# cc13x2_cc26x2 register map
File version: 2.1
CPU: CM4 r0p1, little endian, MPU, FPU, 3 interrupt priority bits
Registers are 32-bit, read-write, reset 0x0 unless marked. A register's access mark holds for its fields unless they carry their own. Offsets are from the block's base; [hi:lo] are bit positions.

## PKA — Integrated module which combines the Public Key Acceleration module, optional True Random Gnerator, optional interrupt controller and a standard bus interface
Base 0x40025000
0x00 APTR — PKA Vector A Address uring execution of basic PKCP operations, this register is double buffered and can be written with a new value for the next operation; when not written, the value remains intact. During the execution of sequencer-controlled complex operations, this register may not be written and its value is undefined at the conclusion of the operation. The driver software cannot rely on the written value to remain intact.
  [10:0] APTR
0x04 BPTR — PKA Vector B Address uring execution of basic PKCP operations, this register is double buffered and can be written with a new value for the next operation; when not written, the value remains intact. During the execution of sequencer-controlled complex operations, this register may not be written and its value is undefined at the conclusion of the operation. The driver software cannot rely on the written value to remain intact.
  [10:0] BPTR
0x08 CPTR — PKA Vector C Address uring execution of basic PKCP operations, this register is double buffered and can be written with a new value for the next operation; when not written, the value remains intact. During the execution of sequencer-controlled complex operations, this register may not be written and its value is undefined at the conclusion of the operation. The driver software cannot rely on the written value to remain intact.
  [10:0] CPTR
0x0C DPTR — PKA Vector D Address uring execution of basic PKCP operations, this register is double buffered and can be written with a new value for the next operation; when not written, the value remains intact. During the execution of sequencer-controlled complex operations, this register may not be written and its value is undefined at the conclusion of the operation. The driver software cannot rely on the written value to remain intact.
  [10:0] DPTR
0x10 ALENGTH — PKA Vector A Length uring execution of basic PKCP operations, this register is double buffered and can be written with a new value for the next operation; when not written, the value remains intact. During the execution of sequencer-controlled complex operations, this register may not be written and its value is undefined at the conclusion of the operation. The driver software cannot rely on the written value to remain intact.
  [8:0] ALENGTH
0x14 BLENGTH — PKA Vector B Length uring execution of basic PKCP operations, this register is double buffered and can be written with a new value for the next operation; when not written, the value remains intact. During the execution of sequencer-controlled complex operations, this register may not be written and its value is undefined at the conclusion of the operation. The driver software cannot rely on the written value to remain intact.
  [8:0] BLENGTH
0x18 SHIFT — PKA Bit Shift Value or basic PKCP operations, modifying the contents of this register is made impossible while the operation is being performed. For the ExpMod-variable and ExpMod-CRT operations, this register is used to indicate the number of odd powers to use (directly as a value in the range 1-16). For the ModInv and ECC operations, this register is used to hold a completion code.
  [4:0] NUM_BITS_TO_SHIFT
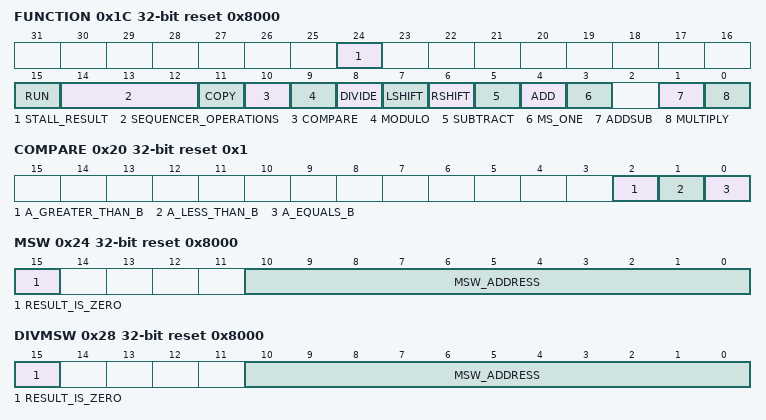
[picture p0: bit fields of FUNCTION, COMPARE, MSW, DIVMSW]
0x1C FUNCTION reset 0x8000 — PKA Function his register contains the control bits to start basic PKCP as well as complex sequencer operations. The run bit can be used to poll for the completion of the operation. Modifying bits [11:0] is made impossible during the execution of a basic PKCP operation. uring the execution of sequencer-controlled complex operations, this register is modified, the run and stall result bits are set to zero at the conclusion, but other bits are undefined. OTE: Continuously reading this register to poll the run bit is not allowed when executing complex sequencer operations (the sequencer cannot access the PKCP when this is done). Leave at least one sysclk cycle between poll operations.
  [24] STALL_RESULT, [15] RUN, [14:12] SEQUENCER_OPERATIONS, [11] COPY, [10] COMPARE, [9] MODULO, [8] DIVIDE, [7] LSHIFT, [6] RSHIFT, [5] SUBTRACT, [4] ADD, [3] MS_ONE, [1] ADDSUB, [0] MULTIPLY
0x20 COMPARE ro reset 0x1 — PKA compare result his register provides the result of a basic PKCP compare operation. It is updated when the FUNCTION.RUN bit is reset at the end of that operation. tatus after a complex sequencer operation is unknown
  [2] A_GREATER_THAN_B, [1] A_LESS_THAN_B, [0] A_EQUALS_B
0x24 MSW ro reset 0x8000 — PKA most-significant-word of result vector his register indicates the (word) address in the PKA RAM where the most significant nonzero 32-bit word of the result is stored. Should be ignored for modulo operations. For basic PKCP operations, this register is updated FUNCTION.RUN bit is reset at the end of the operation. For the complex-sequencer controlled operations, updating of the final value matching the actual result is done near the end of the operation; note that the result is only meaningful if no errors were detected and that for ECC operations, this register will provide information for the x-coordinate of the result point only.
  [15] RESULT_IS_ZERO, [10:0] MSW_ADDRESS
0x28 DIVMSW ro reset 0x8000 — PKA most-significant-word of divide remainder his register indicates the (32-bit word) address in the PKA RAM where the most significant nonzero 32-bit word of the remainder result for the basic divide and modulo operations is stored. Bits [4:0] are loaded with the bit number of the most-significant nonzero bit in the most-significant nonzero word when MS one control bit is set. For divide, modulo, and MS one reporting, this register is updated when FUNCTION.RUN bit is reset at the end of the operation. For the complex sequencer controlled operations, updating of bits [4:0] of this register with the most-significant bit location of the actual result is done near the end of the operation. The result is meaningful only if no errors were detected and that for ECC operations; this register provides information for the x-coordinate of the result point only.
  [15] RESULT_IS_ZERO, [10:0] MSW_ADDRESS
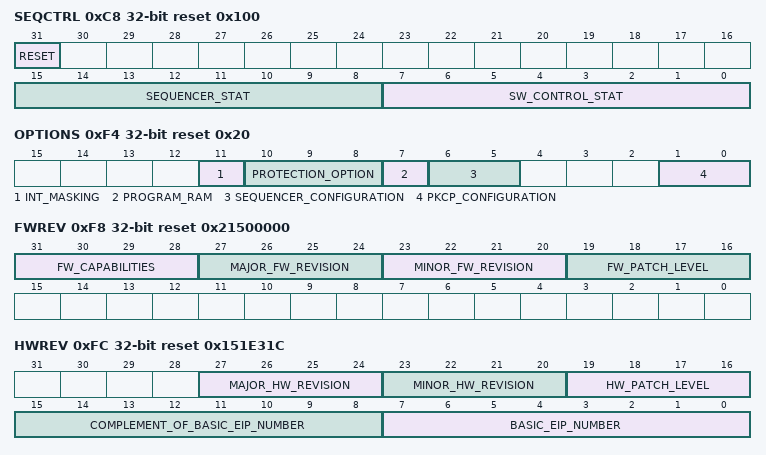
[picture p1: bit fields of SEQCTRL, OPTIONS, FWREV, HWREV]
0xC8 SEQCTRL reset 0x100 — PKA sequencer control and status register he sequencer is interfaced with the outside world through a single control and status register. With the exception of bit [31], the actual use of bits in the separate sub-fields of this register is determined by the sequencer firmware. This register need only be accessed when the sequencer program is stored in RAM. The reset value of the RESET bit depends upon the option chosen for sequencer program storage. NOTE: For Agama the sequencer firmware is executed from ROM.
  [31] RESET, [15:8] SEQUENCER_STAT, [7:0] SW_CONTROL_STAT
0xF4 OPTIONS ro reset 0x20 — PKA hardware options register his register provides the host with a means to determine the hardware configuration implemented in this PKA engine, focused on options that have an effect on software interacting with the module.
  [11] INT_MASKING, [10:8] PROTECTION_OPTION, [7] PROGRAM_RAM, [6:5] SEQUENCER_CONFIGURATION, [1:0] PKCP_CONFIGURATION
0xF8 FWREV ro reset 0x21500000 — PKA firmware revision and capabilities register his register allows the host access to the internal firmware revision number of the PKA Engine for software driver matching and diagnostic purposes. This register also contains a field that encodes the capabilities of the embedded firmware. his register is written by the firmware within a few clock cycles after starting up that firmware. The hardware reset value is zero, indicating that the information has not been written yet.
  [31:28] FW_CAPABILITIES, [27:24] MAJOR_FW_REVISION, [23:20] MINOR_FW_REVISION, [19:16] FW_PATCH_LEVEL
0xFC HWREV ro reset 0x151E31C — PKA hardware revision register his register allows the host access to the hardware revision number of the PKA engine for software driver matching and diagnostic purposes. It is always located at the highest address in the access space of the module and contains an encoding of the EIP number (with its complement as signature) for recognition of the hardware module.
  [27:24] MAJOR_HW_REVISION, [23:20] MINOR_HW_REVISION, [19:16] HW_PATCH_LEVEL, [15:8] COMPLEMENT_OF_BASIC_EIP_NUMBER, [7:0] BASIC_EIP_NUMBER
